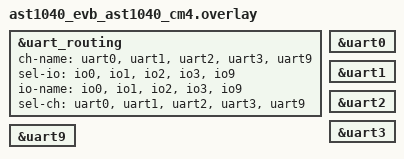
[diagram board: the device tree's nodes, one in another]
&uart_routing {
	status = "okay";

	ch-name = "uart0", "uart1", "uart2", "uart3", "uart9";
	sel-io  = "io0",   "io1",   "io2",   "io3",   "io9";

	io-name = "io0", "io1", "io2", "io3", "io9";
	sel-ch  = "uart0", "uart1", "uart2", "uart3", "uart9";
};

&uart0 {
	status = "okay";
};

&uart1 {
	status = "okay";
};

&uart2 {
	status = "okay";
};

&uart3 {
	status = "okay";
};

&uart9 {
	status = "okay";
};
